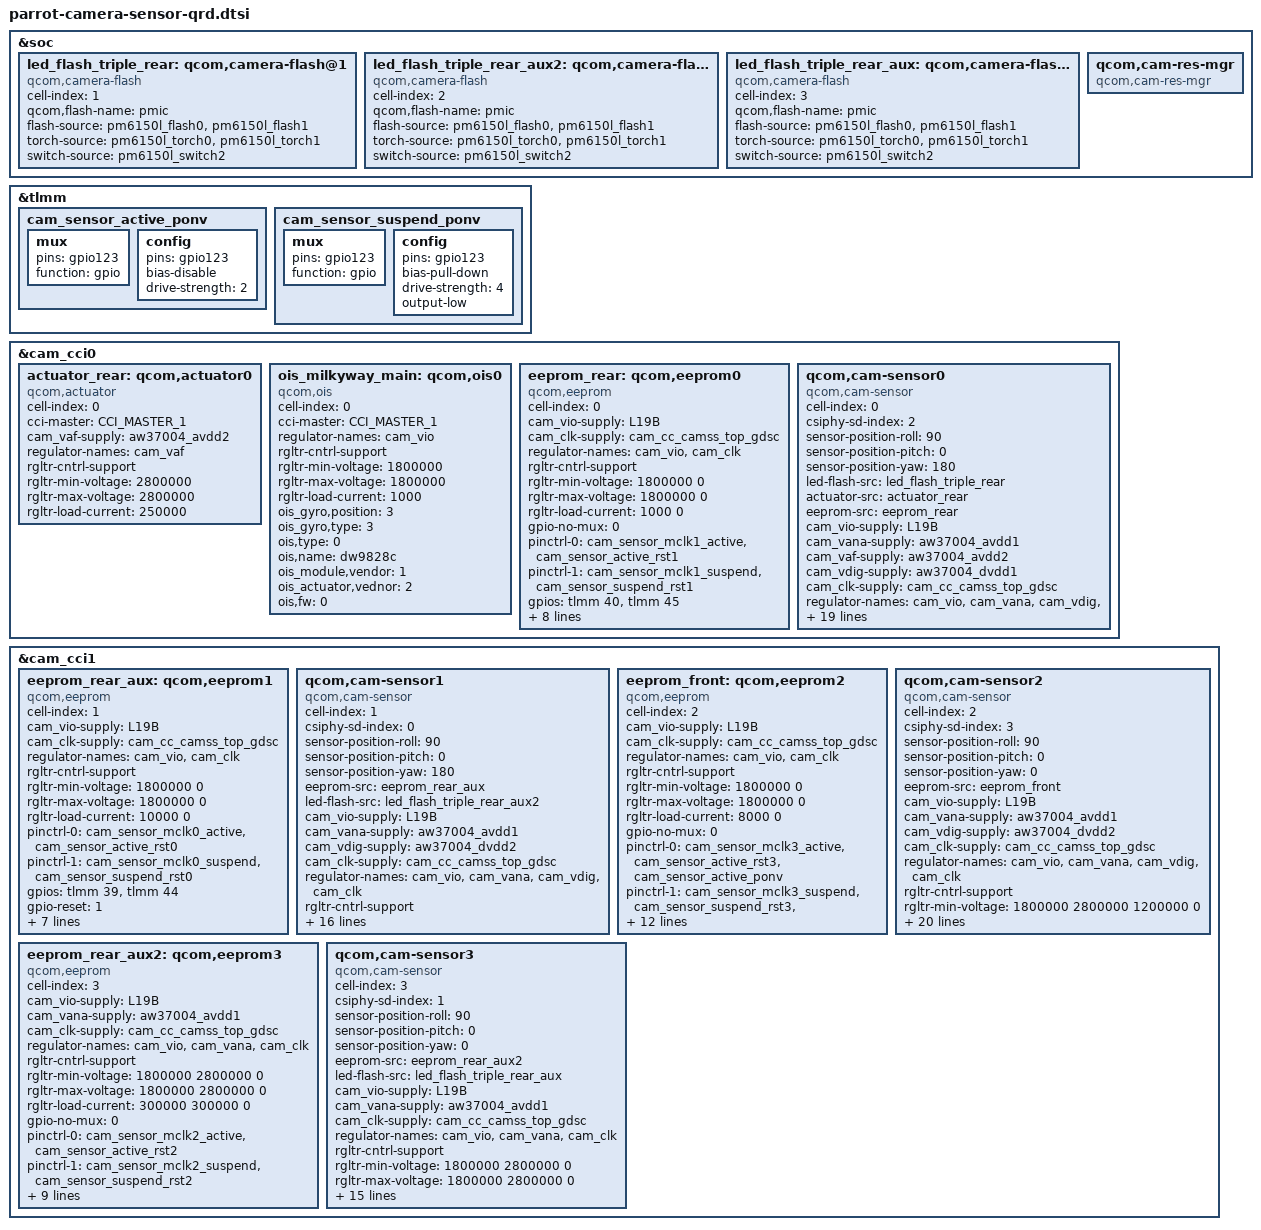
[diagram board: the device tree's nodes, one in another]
#include <dt-bindings/clock/qcom,camcc-parrot.h>
#include <dt-bindings/msm-camera.h>


&soc {
	led_flash_triple_rear: qcom,camera-flash@1 {
		cell-index = <1>;
		compatible = "qcom,camera-flash";
		qcom,flash-name = "pmic";
		flash-source = <&pm6150l_flash0 &pm6150l_flash1>;
		torch-source = <&pm6150l_torch0 &pm6150l_torch1>;
		switch-source = <&pm6150l_switch2>;
		status = "ok";
	};

	led_flash_triple_rear_aux2: qcom,camera-flash@2 {
		cell-index = <2>;
		compatible = "qcom,camera-flash";
		qcom,flash-name = "pmic";
		flash-source = <&pm6150l_flash0 &pm6150l_flash1>;
		torch-source = <&pm6150l_torch0 &pm6150l_torch1>;
		switch-source = <&pm6150l_switch2>;
		status = "ok";
	};

	led_flash_triple_rear_aux: qcom,camera-flash@3 {
		cell-index = <3>;
		compatible = "qcom,camera-flash";
		qcom,flash-name = "pmic";
		flash-source = <&pm6150l_flash0 &pm6150l_flash1>;
		torch-source = <&pm6150l_torch0 &pm6150l_torch1>;
		switch-source = <&pm6150l_switch2>;
		status = "ok";
	};

	qcom,cam-res-mgr {
		compatible = "qcom,cam-res-mgr";
		status = "ok";
	};

};

&tlmm{
/********************front PONV********************/
	cam_sensor_active_ponv: cam_sensor_active_ponv {
		/* PONV */
		mux {
			pins = "gpio123";
			function = "gpio";
		};

		config {
			pins = "gpio123";
			bias-disable;  /* NO PULL */
			drive-strength = <2>; /* 2 MA */
			/*output-high;*/
		};
	};

	cam_sensor_suspend_ponv: cam_sensor_suspend_ponv {
		/* PONV */
		mux {
			pins = "gpio123";
			function = "gpio";
		};

		config {
			pins = "gpio123";
			bias-pull-down; /* PULL DOWN  */
			drive-strength = <4>; /* 2 MA */
			output-low;
		};
	};
};

&cam_cci0 {
	actuator_rear: qcom,actuator0 {
		cell-index = <0>;
		compatible = "qcom,actuator";
		cci-master = <CCI_MASTER_1>;
		cam_vaf-supply = <&aw37004_avdd2>;
		regulator-names = "cam_vaf";
		rgltr-cntrl-support;
		rgltr-min-voltage = <2800000>;
		rgltr-max-voltage = <2800000>;
		rgltr-load-current = <250000>;
		status = "ok";

	};

	ois_milkyway_main: qcom,ois0 {
		cell-index = <0>;
		compatible = "qcom,ois";
		cci-master = <CCI_MASTER_1>;
		//cam_vio-supply = <&L13A>;
		regulator-names = "cam_vio";
		rgltr-cntrl-support;
		rgltr-min-voltage = <1800000>;
		rgltr-max-voltage = <1800000>;
		rgltr-load-current = <1000>;
		ois_gyro,position=<3>;
		ois_gyro,type=<3>;
		ois,type=<0>;
		ois,name="dw9828c";
		ois_module,vendor=<1>;
		ois_actuator,vednor=<2>;
		ois,fw=<0>;
		status = "ok";
	};

	eeprom_rear: qcom,eeprom0 {
		cell-index = <0>;
		compatible = "qcom,eeprom";
		cam_vio-supply = <&L19B>;
		cam_clk-supply = <&cam_cc_camss_top_gdsc>;
		regulator-names = "cam_vio","cam_clk";
		rgltr-cntrl-support;
		rgltr-min-voltage = <1800000 0>;
		rgltr-max-voltage = <1800000 0>;
		rgltr-load-current = <1000 0>;
		gpio-no-mux = <0>;
		pinctrl-names = "cam_default", "cam_suspend";
		pinctrl-0 = <&cam_sensor_mclk1_active
				 &cam_sensor_active_rst1>;
		pinctrl-1 = <&cam_sensor_mclk1_suspend
				 &cam_sensor_suspend_rst1>;
		gpios = <&tlmm 40 0>,
			<&tlmm 45 0>;
		gpio-reset = <1>;
		gpio-req-tbl-num = <0 1>;
		gpio-req-tbl-flags = <1 0>;
		gpio-req-tbl-label = "CAMIF_MCLK1",
					"CAM_RESET1";
		cci-master = <CCI_MASTER_1>;
		clocks = <&camcc CAM_CC_MCLK1_CLK>;
		clock-names = "cam_clk";
		clock-cntl-level = "nominal";
		clock-rates = <24000000>;
		status = "ok";

	};

	/* Rear*/

	qcom,cam-sensor0 {
		cell-index = <0>;
		compatible = "qcom,cam-sensor";
		csiphy-sd-index = <2>;
		sensor-position-roll = <90>;
		sensor-position-pitch = <0>;
		sensor-position-yaw = <180>;
		led-flash-src = <&led_flash_triple_rear>;
		actuator-src = <&actuator_rear>;
		//ois-src = <&ois_milkyway_main>;
		eeprom-src = <&eeprom_rear>;
		cam_vio-supply = <&L19B>;
		cam_vana-supply = <&aw37004_avdd1>;
		cam_vaf-supply = <&aw37004_avdd2>;
		cam_vdig-supply = <&aw37004_dvdd1>;
		cam_clk-supply = <&cam_cc_camss_top_gdsc>;
		regulator-names = "cam_vio", "cam_vana", "cam_vdig", "cam_clk";
		rgltr-cntrl-support;
		rgltr-min-voltage = <1800000 2800000 1200000 0>;
		rgltr-max-voltage = <1800000 2800000 1200000 0>;
		rgltr-load-current = <300000 3000000 1200000 0>;
		gpio-no-mux = <0>;
		pinctrl-names = "cam_default", "cam_suspend";
		pinctrl-0 = <&cam_sensor_mclk1_active
				 &cam_sensor_active_rst1>;
		pinctrl-1 = <&cam_sensor_mclk1_suspend
				 &cam_sensor_suspend_rst1>;
		gpios = <&tlmm 40 0>,
			<&tlmm 45 0>;
		gpio-reset = <1>;
		gpio-req-tbl-num = <0 1>;
		gpio-req-tbl-flags = <1 0>;
		gpio-req-tbl-label = "CAMIF_MCLK1",
					"CAM_RESET1";
		cci-master = <CCI_MASTER_1>;
		clocks = <&camcc CAM_CC_MCLK1_CLK>;
		clock-names = "cam_clk";
		clock-cntl-level = "nominal";
		clock-rates = <24000000>;
		status = "ok";
	};
};

&cam_cci1 {

	eeprom_rear_aux: qcom,eeprom1 {
		cell-index = <1>;
		compatible = "qcom,eeprom";
		cam_vio-supply = <&L19B>;
		cam_clk-supply = <&cam_cc_camss_top_gdsc>;
		regulator-names = "cam_vio","cam_clk";
		rgltr-cntrl-support;
		rgltr-min-voltage = <1800000 0>;
		rgltr-max-voltage = <1800000 0>;
		rgltr-load-current = <10000 0>;
		pinctrl-names = "cam_default", "cam_suspend";
		pinctrl-0 = <&cam_sensor_mclk0_active
				&cam_sensor_active_rst0>;
		pinctrl-1 = <&cam_sensor_mclk0_suspend
				&cam_sensor_suspend_rst0>;
		gpios = <&tlmm 39 0>,
			<&tlmm 44 0>;
		gpio-reset = <1>;
		gpio-req-tbl-num = <0 1>;
		gpio-req-tbl-flags = <1 0>;
		gpio-req-tbl-label = "CAMIF_MCLK0",
					"CAM_RESET0";
		cci-master = <CCI_MASTER_0>;
		clocks = <&camcc CAM_CC_MCLK0_CLK>;
		clock-names = "cam_clk";
		clock-cntl-level = "nominal";
		clock-rates = <24000000>;
		status = "ok";

	};
	/*Rear Aux*/
	qcom,cam-sensor1 {
		cell-index = <1>;
		compatible = "qcom,cam-sensor";
		csiphy-sd-index = <0>;
		sensor-position-roll = <90>;
		sensor-position-pitch = <0>;
		sensor-position-yaw = <180>;
		eeprom-src = <&eeprom_rear_aux>;
		led-flash-src = <&led_flash_triple_rear_aux2>;
		cam_vio-supply = <&L19B>;
		cam_vana-supply = <&aw37004_avdd1>;
		cam_vdig-supply = <&aw37004_dvdd2>;
		cam_clk-supply = <&cam_cc_camss_top_gdsc>;
		regulator-names = "cam_vio", "cam_vana", "cam_vdig", "cam_clk";
		rgltr-cntrl-support;
		rgltr-min-voltage = <1800000 2800000 1200000 0>;
		rgltr-max-voltage = <1800000 2800000 1200000 0>;
		rgltr-load-current = <300000 300000 1200000 0>;
		pinctrl-names = "cam_default", "cam_suspend";
		pinctrl-0 = <&cam_sensor_mclk0_active
				&cam_sensor_active_rst0>;
		pinctrl-1 = <&cam_sensor_mclk0_suspend
				&cam_sensor_suspend_rst0>;
		gpios = <&tlmm 39 0>,
			<&tlmm 44 0>;
		gpio-reset = <1>;
		gpio-req-tbl-num = <0 1>;
		gpio-req-tbl-flags = <1 0>;
		gpio-req-tbl-label = "CAMIF_MCLK0",
					"CAM_RESET0";
		cci-master = <CCI_MASTER_0>;
		clocks = <&camcc CAM_CC_MCLK0_CLK>;
		clock-names = "cam_clk";
		clock-cntl-level = "nominal";
		clock-rates = <24000000>;
		status = "ok";
	};
	eeprom_front: qcom,eeprom2 {
		cell-index = <2>;
		compatible = "qcom,eeprom";
		cam_vio-supply = <&L19B>;
		cam_clk-supply = <&cam_cc_camss_top_gdsc>;
		regulator-names = "cam_vio","cam_clk";
		rgltr-cntrl-support;
		rgltr-min-voltage = <1800000 0>;
		rgltr-max-voltage = <1800000 0>;
		rgltr-load-current = <8000 0>;
		gpio-no-mux = <0>;
		pinctrl-names = "cam_default", "cam_suspend";
		pinctrl-0 = <&cam_sensor_mclk3_active
				 &cam_sensor_active_rst3
				 &cam_sensor_active_ponv>;
		pinctrl-1 = <&cam_sensor_mclk3_suspend
				 &cam_sensor_suspend_rst3
				 &cam_sensor_suspend_ponv>;
		gpios = <&tlmm 42 0>,
			<&tlmm 47 0>,
			<&tlmm 123 0>;
		gpio-reset = <1>;
		gpio-custom1 = <2>;
		gpio-req-tbl-num = <0 1 2>;
		gpio-req-tbl-flags = <1 0 0>;
		gpio-req-tbl-label = "CAMIF_MCLK3",
					"CAM_RESET3",
					"CAM_PONV";
		cci-master = <CCI_MASTER_1>;
		clocks = <&camcc CAM_CC_MCLK3_CLK>;
		clock-names = "cam_clk";
		clock-cntl-level = "nominal";
		clock-rates = <24000000>;
		status = "ok";

	};

	/*Front*/
	qcom,cam-sensor2 {
		cell-index = <2>;
		compatible = "qcom,cam-sensor";
		csiphy-sd-index = <3>;
		sensor-position-roll = <90>;
		sensor-position-pitch = <0>;
		sensor-position-yaw = <0>;
		eeprom-src = <&eeprom_front>;
		cam_vio-supply = <&L19B>;
		cam_vana-supply = <&aw37004_avdd1>;
		cam_vdig-supply = <&aw37004_dvdd2>;
		cam_clk-supply = <&cam_cc_camss_top_gdsc>;
		regulator-names = "cam_vio", "cam_vana", "cam_vdig", "cam_clk";
		rgltr-cntrl-support;
		rgltr-min-voltage = <1800000 2800000 1200000 0>;
		rgltr-max-voltage = <1800000 2800000 1200000 0>;
		rgltr-load-current = <300000 300000 120000 0>;
		gpio-no-mux = <0>;
		pinctrl-names = "cam_default", "cam_suspend";
		pinctrl-0 = <&cam_sensor_mclk3_active
				 &cam_sensor_active_rst3
				 &cam_sensor_active_ponv>;
		pinctrl-1 = <&cam_sensor_mclk3_suspend
				 &cam_sensor_suspend_rst3
				 &cam_sensor_suspend_ponv>;
		gpios = <&tlmm 42 0>,
			<&tlmm 47 0>,
			<&tlmm 123 0>;
		gpio-reset = <1>;
		gpio-custom1 = <2>;
		gpio-req-tbl-num = <0 1 2>;
		gpio-req-tbl-flags = <1 0 0>;
		gpio-req-tbl-label = "CAMIF_MCLK3",
					"CAM_RESET3",
					"CAM_PONV";
		cci-master = <CCI_MASTER_1>;
		clocks = <&camcc CAM_CC_MCLK3_CLK>;
		clock-names = "cam_clk";
		clock-cntl-level = "nominal";
		clock-rates = <24000000>;
		status = "ok";
	};

	eeprom_rear_aux2: qcom,eeprom3 {
		cell-index = <3>;
		compatible = "qcom,eeprom";
		cam_vio-supply = <&L19B>;
		cam_vana-supply = <&aw37004_avdd1>;
		cam_clk-supply = <&cam_cc_camss_top_gdsc>;
		regulator-names = "cam_vio", "cam_vana", "cam_clk";
		rgltr-cntrl-support;
		rgltr-min-voltage = <1800000 2800000 0>;
		rgltr-max-voltage = <1800000 2800000 0>;
		rgltr-load-current = <300000 300000 0>;
		gpio-no-mux = <0>;
		pinctrl-names = "cam_default", "cam_suspend";
		pinctrl-0 = <&cam_sensor_mclk2_active
				 &cam_sensor_active_rst2>;
		pinctrl-1 = <&cam_sensor_mclk2_suspend
				 &cam_sensor_suspend_rst2>;
		gpios = <&tlmm 41 0>,
			<&tlmm 46 0>;
		gpio-reset = <1>;
		gpio-req-tbl-num = <0 1>;
		gpio-req-tbl-flags = <1 0>;
		gpio-req-tbl-label = "CAMIF_MCLK2",
					"CAM_RESET2";
		cci-master = <CCI_MASTER_0>;
		clocks = <&camcc CAM_CC_MCLK2_CLK>;
		clock-names = "cam_clk";
		clock-cntl-level = "nominal";
		clock-rates = <24000000>;
		status = "ok";

	};

	/*Rear Aux2*/
	qcom,cam-sensor3 {
		cell-index = <3>;
		compatible = "qcom,cam-sensor";
		csiphy-sd-index = <1>;
		sensor-position-roll = <90>;
		sensor-position-pitch = <0>;
		sensor-position-yaw = <0>;
		eeprom-src = <&eeprom_rear_aux2>;
		led-flash-src = <&led_flash_triple_rear_aux>;
		cam_vio-supply = <&L19B>;
		cam_vana-supply = <&aw37004_avdd1>;
		cam_clk-supply = <&cam_cc_camss_top_gdsc>;
		regulator-names = "cam_vio", "cam_vana", "cam_clk";
		rgltr-cntrl-support;
		rgltr-min-voltage = <1800000 2800000 0>;
		rgltr-max-voltage = <1800000 2800000 0>;
		rgltr-load-current = <300000 300000 0>;
		gpio-no-mux = <0>;
		pinctrl-names = "cam_default", "cam_suspend";
		pinctrl-0 = <&cam_sensor_mclk2_active
				 &cam_sensor_active_rst2>;
		pinctrl-1 = <&cam_sensor_mclk2_suspend
				 &cam_sensor_suspend_rst2>;
		gpios = <&tlmm 41 0>,
			<&tlmm 46 0>;
		gpio-reset = <1>;
		gpio-req-tbl-num = <0 1>;
		gpio-req-tbl-flags = <1 0>;
		gpio-req-tbl-label = "CAMIF_MCLK2",
					"CAM_RESET2";
		cci-master = <CCI_MASTER_0>;
		clocks = <&camcc CAM_CC_MCLK2_CLK>;
		clock-names = "cam_clk";
		clock-cntl-level = "nominal";
		clock-rates = <24000000>;
		status = "ok";
	};
};
